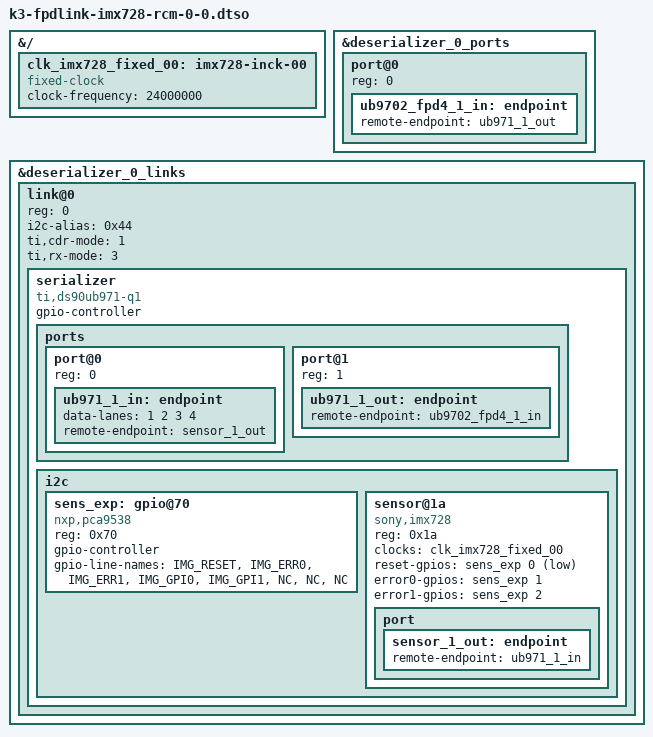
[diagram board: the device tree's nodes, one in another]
// SPDX-License-Identifier: GPL-2.0
/*
 * D3 IMX728 FPD-Link 4 Camera Module
 *
 * Copyright (c) 2024 Define Design Deploy Corp - https://www.d3embedded.com
 */

/dts-v1/;
/plugin/;

#include <dt-bindings/gpio/gpio.h>

&{/} {
	clk_imx728_fixed_00: imx728-inck-00 {
		compatible = "fixed-clock";
		#clock-cells = <0>;
		clock-frequency = <24000000>;
	};
};

&deserializer_0_ports {
	#address-cells = <1>;
	#size-cells = <0>;

	/* FPDLink RX 0 */
	port@0 {
		reg = <0>;
		ub9702_fpd4_1_in: endpoint {
			remote-endpoint = <&ub971_1_out>;
		};
	};
};

&deserializer_0_links {
	#address-cells = <1>;
	#size-cells = <0>;

	link@0 {
		reg = <0>;
		i2c-alias = <0x44>;

		ti,cdr-mode = <1>;
		ti,rx-mode = <3>;

		serializer: serializer {
			compatible = "ti,ds90ub971-q1";
			gpio-controller;
			#gpio-cells = <2>;

			#clock-cells = <0>;

			ports {
				#address-cells = <1>;
				#size-cells = <0>;

				port@0 {
					reg = <0>;
					ub971_1_in: endpoint {
						data-lanes = <1 2 3 4>;
						remote-endpoint = <&sensor_1_out>;
					};
				};

				port@1 {
					reg = <1>;

					ub971_1_out: endpoint {
						remote-endpoint = <&ub9702_fpd4_1_in>;
					};
				};
			};

			i2c {
				#address-cells = <1>;
				#size-cells = <0>;

				sens_exp: gpio@70 {
					compatible = "nxp,pca9538";
					reg = <0x70>;
					gpio-controller;
					#gpio-cells = <2>;
					gpio-line-names = "IMG_RESET", "IMG_ERR0",
							  "IMG_ERR1", "IMG_GPI0",
							  "IMG_GPI1", "NC",
							  "NC", "NC";
				};

				sensor@1a {
					compatible = "sony,imx728";
					reg = <0x1a>;

					clocks = <&clk_imx728_fixed_00>;
					clock-names = "inck";

					reset-gpios = <&sens_exp 0 GPIO_ACTIVE_LOW>;
					error0-gpios = <&sens_exp 1 GPIO_ACTIVE_HIGH>;
					error1-gpios = <&sens_exp 2 GPIO_ACTIVE_HIGH>;

					port {
						sensor_1_out: endpoint {
							remote-endpoint = <&ub971_1_in>;
						};
					};
				};
			};
		};
	};
};
